# M481_v1 register map
File version: 1.0
Registers are 32-bit, read-write, reset 0x0 unless marked. A register's access mark holds for its fields unless they carry their own. Offsets are from the block's base; [hi:lo] are bit positions; {n}, {i} and the like mark numbered series.

## CCAP — CCAP Register Map
Base 0x40030000
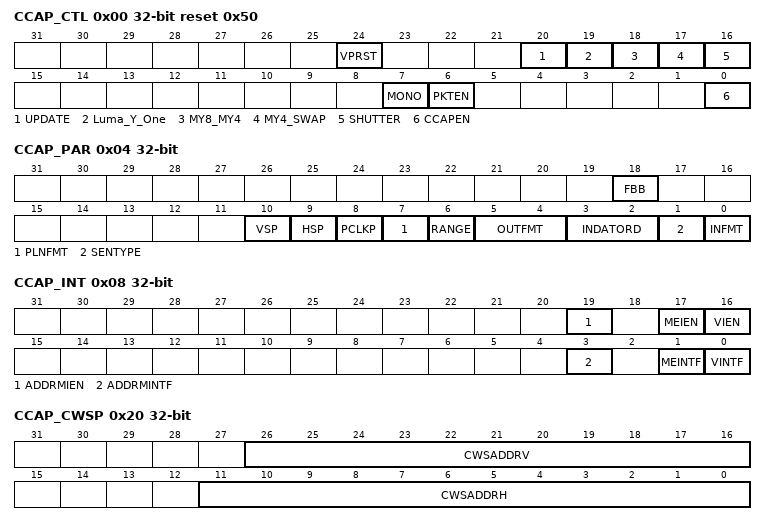
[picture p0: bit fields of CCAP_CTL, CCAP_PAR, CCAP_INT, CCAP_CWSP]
0x00 CCAP_CTL reset 0x50 — Camera Capture Interface Control Register
  [24] VPRST — Capture Interface Reset
    0=Capture interface reset Disabled; 1=Capture interface reset Enabled
  [20] UPDATE — Update Register at New Frame
    0=Update register at new frame Disabled; 1=Update register at new frame Enabled (auto cleared to 0 when register updated)
  [19] Luma_Y_One — Color/Monochrome CMOS Sensor Luminance 8-bit Y to 1-bit Y Conversion. Note: Color CMOS sensor U/V components are ignored when the Luma_Y_One is enabled.
    0=Color/Monochrome CMOS sensor Luma-Y-One bit Disabled; 1=Color/Monochrome CMOS sensor Luma-Y-One bit Enabled
  [18] MY8_MY4 — Monochrome CMOS Sensor Data I/O Interface
    0=Monochrome CMOS sensor is by the 4-bit data I/O interface; 1=Monochrome CMOS sensor is by the 8-bit data I/O interface
  [17] MY4_SWAP — Monochrome CMOS Sensor 4-bit Data Nibble Swap
    0=The 4-bit data input sequence: 1st Pixel is for 1st Nibble (1st pixel @MSB); 1=The 4-bit data input sequence: 1st Pixel is for 2nd Nibble (1st pixel @LSB)
  [16] SHUTTER — Camera Capture Interface Automatically Disable the Capture Inteface After a Frame Had Been Captured
    0=Shutter Disabled; 1=Shutter Enabled
  [7] MONO — Monochrome CMOS Sensor Select
    0=Color CMOS Sensor; 1=Monochrome CMOS Sensor. The U/V components are ignored when the MONO is enabled
  [6] PKTEN — Packet Output Enable Bit
    0=Packet output Disabled; 1=Packet output Enabled
  [0] CCAPEN — Camera Capture Interface Enable Bit
    0=Camera Capture Interface Disabled; 1=Camera Capture Interface Enabled
0x04 CCAP_PAR — Camera Capture Interface Parameter Register
  [18] FBB — Field by Blank (Only in Ccir-656 Mode). Field by Blank means blanking pixel data(0x80108010) have to transfer to system memory or not
    0=Field by blank Disabled.(blank pixel data will transfer to system memory); 1=Field by blank Enabled. (only active data will transfer to system memory)
  [10] VSP — Sensor Vsync Polarity
    0=Sync Low; 1=Sync High
  [9] HSP — Sensor Hsync Polarity
    0=Sync Low; 1=Sync High
  [8] PCLKP — Sensor Pixel Clock Polarity
    0=Input video data and signals are latched by falling edge of Pixel Clock; 1=Input video data and signals are latched by rising edge of Pixel Clock
  [7] PLNFMT — Planar Output YUV Format
    0=YUV422; 1=YUV420
  [6] RANGE — Scale Input YUV CCIR601 Color Range to Full Range
    0=Default; 1=Scale to full range
  [5:4] OUTFMT — Image Data Format Output to System Memory
    0=YCbCr422; 1=Only output Y. (Select this format when CCAP_CTL 'Luma_Y_One' or 'MONO' enabled); 2=RGB555; 3=RGB565
  [3:2] INDATORD — Sensor Input Data Order. Sensor input data (Byte 1) is {B[4:0], G[5:3]}.
    0=Sensor input data (Byte 0 1 2 3) is Y0 U0 Y1 V0. Sensor input data (Byte 0) is {R[4:0],G[5:3]},; 1=Sensor input data (Byte 0 1 2 3) is Y0 V0 Y1 U0. Sensor input data (Byte 0) is {B[4:0],G[5:3]},; 2=Sensor input data (Byte 0 1 2 3) is U0 Y0 V0 Y1. Sensor input data (Byte 0) is {G[2:0],B[4:0]},; 3=Sensor input data (Byte 0 1 2 3) is V0 Y0 U0 Y1. Sensor input data (Byte 0) is {G[2:0],R[4:0]},
  [1] SENTYPE — Sensor Input Type
    0=CCIR601; 1=CCIR656, Vsync Hsync embedded in the data signal
  [0] INFMT — Sensor Input Data Format
    0=YCbCr422; 1=RGB565
0x08 CCAP_INT — Camera Capture Interface Interrupt Register
  [19] ADDRMIEN — Address Match Interrupt Enable Bit
    0=Address match interrupt Disabled; 1=Address match interrupt Enabled
  [17] MEIEN — Bus Master Transfer Error Interrupt Enable Bit
    0=Bus Master Transfer error interrupt Disabled; 1=Bus Master Transfer error interrupt Enabled
  [16] VIEN — Video Frame End Interrupt Enable Bit
    0=Video frame end interrupt Disabled; 1=Video frame end interrupt Enabled
  [3] ADDRMINTF — Memory Address Match Interrupt. Note: This bit is cleared by writing 1 to it.
    0=Memory Address Match Interrupt did not occur; 1=Memory Address Match Interrupt occurred
  [1] MEINTF — Bus Master Transfer Error Interrupt. Note: This bit is cleared by writing 1 to it.
    0=Transfer Error did not occur; 1=Transfer Error occurred
  [0] VINTF — Video Frame End Interrupt. Note: This bit is cleared by writing 1 to it.
    0=Did not receive a frame completely; 1=Received a frame completely
0x20 CCAP_CWSP — Cropping Window Starting Address Register
  [26:16] CWSADDRV — Cropping Window Vertical Starting Address. Specify the value of the cropping window vertical start address.
  [11:0] CWSADDRH — Cropping Window Horizontal Starting Address. Specify the value of the cropping window horizontal start address.
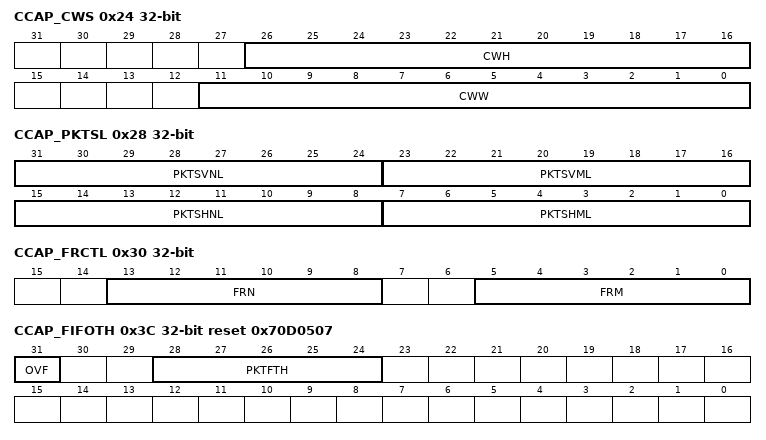
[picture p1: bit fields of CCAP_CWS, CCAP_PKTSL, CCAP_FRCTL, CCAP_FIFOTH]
0x24 CCAP_CWS — Cropping Window Size Register
  [26:16] CWH — Cropping Window Height. Specify the size of the cropping window height.
  [11:0] CWW — Cropping Window Width. Specify the size of the cropping window width.
0x28 CCAP_PKTSL — Packet Scaling Vertical/Horizontal Factor Register (LSB)
  [31:24] PKTSVNL — Packet Scaling Vertical Factor n (Lower 8-bit). Specify the lower 8-bit of numerator part (N) of the vertical scaling factor. The lower 8-bit will be cascaded with higher 8-bit (PKDSVNH) to form a 16-bit numerator of vertical factor.
  [23:16] PKTSVML — Packet Scaling Vertical Factor m (Lower 8-bit). Specify the lower 8-bit of denominator part (M) of the vertical scaling factor. The lower 8-bit will be cascaded with higher 8-bit (PKDSVMH) to form a 16-bit denominator (M) of vertical factor. The output image width will be equal to the image height * N/M. Note: The value of N must be equal to or less than M.
  [15:8] PKTSHNL — Packet Scaling Horizontal Factor n (Lower 8-bit). Specify the lower 8-bit of numerator part (N) of the horizontal scaling factor. The lower 8-bit will be cascaded with higher 8-bit (PKDSHNH) to form a 16-bit numerator of horizontal factor.
  [7:0] PKTSHML — Packet Scaling Horizontal Factor m (Lower 8-bit). Specify the lower 8-bit of denominator part (M) of the horizontal scaling factor. The lower 8-bit will be cascaded with higher 8-bit (PKDSHMH) to form a 16-bit denominator (M) of vertical factor. The output image width will be equal to the image width * N/M. Note: The value of N must be equal to or less than M.
0x30 CCAP_FRCTL — Scaling Frame Rate Factor Register
  [13:8] FRN — Scaling Frame Rate Factor n. Specify the denominator part (N) of the frame rate scaling factor.
  [5:0] FRM — Scaling Frame Rate Factor M. Specify the denominator part (M) of the frame rate scaling factor. The output image frame rate will be equal to input image frame rate * (N/M). Note: The value of N must be equal to or less than M.
0x34 CCAP_STRIDE — Frame Output Pixel Stride Width Register
  [13:0] PKTSTRIDE — Packet Frame Output Pixel Stride Width. The output pixel stride size of the packet pipe. It is a 32-pixel aligned stride width for the Luma-Y-One bit format or a 4-pixel aligned stride with for the Luma-Y-Eight bit format when color or monochrome CMOS sensors used. This means that every new captured line is by word alignment address when color or monochrome CMOS sensors used.
0x3C CCAP_FIFOTH reset 0x70D0507 — FIFO Threshold Register
  [31] OVF — FIFO Overflow Flag. Indicate the FIFO overflow flag.
  [28:24] PKTFTH — Packet FIFO Threshold. Specify the 5-bit value of the packet FIFO threshold.
0x40 CCAP_CMPADDR reset 0xFFFFFFFC — Compare Memory Base Address Register
  [31:0] CMPADDR — Compare Memory Base Address. It is a word alignment address, that is, the address is aligned by ignoring the 2 LSB bits [1:0].
0x44 CCAP_LUMA_Y1_THD reset 0x80 — Luminance Y8 to Y1 Threshold Value Register
  [7:0] LUMA_Y1_THRESH — Luminance Y8 to Y1 Threshold Value. Specify the 8-bit threshold value for the luminance Y bit-8 to the luminance Y 1-bit conversion.
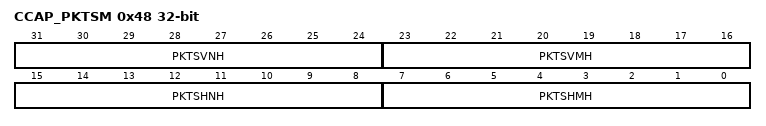
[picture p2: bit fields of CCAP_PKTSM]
0x48 CCAP_PKTSM — Packet Scaling Vertical/Horizontal Factor Register (MSB)
  [31:24] PKTSVNH — Packet Scaling Vertical Factor n (Higher 8-bit). Specify the higher 8-bit of numerator part (N) of the vertical scaling factor. Please refer to the register 'CCAP_PKTSL' to check the cooperation between these two registers.
  [23:16] PKTSVMH — Packet Scaling Vertical Factor m (Higher 8-bit). Specify the lower 8-bit of denominator part (M) of the vertical scaling factor. Please refer to the register 'CCAP_PKTSL' to check the cooperation between these two registers.
  [15:8] PKTSHNH — Packet Scaling Horizontal Factor n (Higher 8-bit). Specify the lower 8-bit of numerator part (N) of the horizontal scaling factor. Please refer to the register 'CCAP_PKTSL' for the detailed operation.
  [7:0] PKTSHMH — Packet Scaling Horizontal Factor m (Higher 8-bit). Specify the lower 8-bit of denominator part (M) of the horizontal scaling factor. Please refer to the register 'CCAP_PKTSL' for the detailed operation.
0x50 CCAP_CURADDRP ro — Current Packet System Memory Address Register
  [31:0] CURADDR — Current Packet Output Memory Address. Speficy the 32-bit value of the current packet output memory address.
0x60 CCAP_PKTBA0 — System Memory Packet Base Address 0 Register
  [31:0] BASEADDR — System Memory Packet Base Address 0. It is a word alignment address, that is, the address is aligned by ignoring the 2 LSB bits [1:0].
